AUTOSAR XML (schema 00050)
package /Safety_Gaurd/ComponentTypes
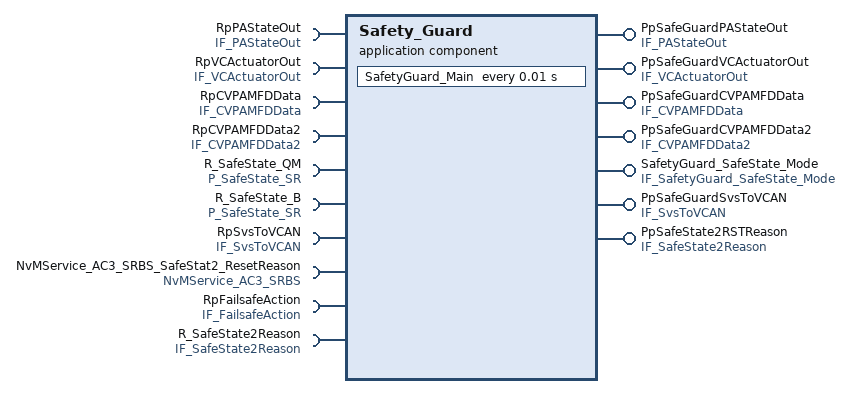
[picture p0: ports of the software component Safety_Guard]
  application sw component type Safety_Guard
    require port RpPAStateOut: nonqueued-receiver-com-spec=data-element=TbAP_PAStateOut_t, required-interface=IF_PAStateOut
    provide port PpSafeGuardPAStateOut: nonqueued-sender-com-spec{data-element=TbAP_PAStateOut_t, init-value=fields=[IeAP_e_PAMChimeRepnRate:0, IeAP_e_PAMVolSig:0, IeAP_e_FrntParkLEDSts:0, IeAP_e_PAMLedCtrl:0, IeAP_e_PAMChimeTyp:0, IeAP_e_ParkSensePopUpReq:0, IeAP_b_PAMRearBrkReq:0, IeAP_b_PAMRearCtrlSts:0]}, provided-interface=IF_PAStateOut
    require port RpVCActuatorOut: nonqueued-receiver-com-spec=data-element=TbAP_VCActuatorOut_t, required-interface=IF_VCActuatorOut
    provide port PpSafeGuardVCActuatorOut: nonqueued-sender-com-spec{data-element=TbAP_VCActuatorOut_t, init-value=fields=[IeAP_nm_StrwTrqReq:0, IeAP_a_DecelMax:0, IeAP_a_DecelMin:0, IeAP_a_JerkDecelMax:0, IeAP_a_JerkDecelMin:0, IeAP_a_AcclMin:0, IeAP_a_AcclMax:0, IeAP_da_JerkAcclMax:0, IeAP_da_JerkAcclMin:0, IeAP_cm_TrgtDist:0, IeAP_kph_TrgtVehSpd:0, IeAP_e_TurnIndicReq:0, IeAP_b_StandstillReq:0]}, provided-interface=IF_VCActuatorOut
    require port RpCVPAMFDData: nonqueued-receiver-com-spec=data-element=IFOD_Outputs_CVPAMFDData_t, required-interface=IF_CVPAMFDData
    require port RpCVPAMFDData2: nonqueued-receiver-com-spec=data-element=LMD_Outputs_CVPAMFDData2_t, required-interface=IF_CVPAMFDData2
    provide port PpSafeGuardCVPAMFDData: nonqueued-sender-com-spec{data-element=IFOD_Outputs_CVPAMFDData_t, init-value=fields=[IeFOD_e_FODHealth:0, IeFOD_e_FODConfidence:0]}, provided-interface=IF_CVPAMFDData
    provide port PpSafeGuardCVPAMFDData2: nonqueued-sender-com-spec{data-element=LMD_Outputs_CVPAMFDData2_t, init-value=fields=[{short-label=LMD_Outputs_ADASFDLANES1_s, fields=[IeLMD_e_FrameIndexLanes1:0, IeLMD_e_CntrAdasFdLanes1:0, IeLMD_e_Line1Confidence:0, IeLMD_e_Line2Confidence:0, IeLMD_e_Line3Confidence:0, IeLMD_e_Line4Confidence:0, IeLMD_m_Line1Offset:0, IeLMD_m_Line2Offset:0, IeLMD_m_Line3Offset:0, IeLMD_m_Line4Offset:0, IeLMD_rad_Line1Heading:0, IeLMD_rad_Line2Heading:0, IeLMD_rad_Line3Heading:0, IeLMD_rad_Line4Heading:0, IeLMD_m_Line1StartRange:0, IeLMD_m_Line2StartRange:0, IeLMD_m_Line3StartRange:0, IeLMD_m_Line4StartRange:0, IeLMD_m_Line1EndRange:0, IeLMD_m_Line2EndRange:0, IeLMD_m_Line3EndRange:0, IeLMD_m_Line4EndRange:0, IeLMD_e_Line1Curvature:0, IeLMD_e_Line2Curvature:0, IeLMD_e_Line3Curvature:0, IeLMD_e_Line4Curvature:0, IeLMD_e_Line1CurvatureRate:0, IeLMD_e_Line2CurvatureRate:0, IeLMD_e_Line3CurvatureRate:0, IeLMD_e_Line4CurvatureRate:0, IeLMD_e_Line1Type:0, IeLMD_e_Line2Type:0, IeLMD_e_Line3Type:0, IeLMD_e_Line4Type:0, IeLMD_e_LaneDetectionHealth:0, IeLMD_e_CameraStatus:0, IeLMD_e_CrcAdasFdLanes1:0, IeLMD_e_MsgCntrAdasFdLanes1:0, IeLMD_e_MacAdasFdLanes1:0, IeLMD_e_ReservedForFunctionalSafety1:0, Dummy1_1_b:0, Dummy2_1_b:0, Dummy3_1_b:0]}, {short-label=LMD_Outputs_ADASFDLANES2_s, fields=[IeLMD_e_FrameIndexLanes2:0, IeLMD_e_CntrAdasFdLanes2:0, IeLMD_e_LineSeg1Conf:0, IeLMD_e_LineSeg2Conf:0, IeLMD_e_LineSeg3Conf:0, IeLMD_e_LineSeg4Conf:0, IeLMD_e_LineSeg5Conf:0, IeLMD_e_LineSeg6Conf:0, IeLMD_e_LineSeg7Conf:0, IeLMD_e_LineSeg8Conf:0, IeLMD_m_LineSeg1X1:0, IeLMD_m_LineSeg2X1:0, IeLMD_m_LineSeg3X1:0, IeLMD_m_LineSeg4X1:0, IeLMD_m_LineSeg5X1:0, IeLMD_m_LineSeg6X1:0, IeLMD_m_LineSeg7X1:0, IeLMD_m_LineSeg8X1:0, IeLMD_m_LineSeg1X2:0, IeLMD_m_LineSeg2X2:0, IeLMD_m_LineSeg3X2:0, IeLMD_m_LineSeg4X2:0, IeLMD_m_LineSeg5X2:0, IeLMD_m_LineSeg6X2:0, IeLMD_m_LineSeg7X2:0, IeLMD_m_LineSeg8X2:0, IeLMD_m_LineSeg1Y1:0, IeLMD_m_LineSeg2Y1:0, IeLMD_m_LineSeg3Y1:0, IeLMD_m_LineSeg4Y1:0, IeLMD_m_LineSeg5Y1:0, IeLMD_m_LineSeg6Y1:0, IeLMD_m_LineSeg7Y1:0, IeLMD_m_LineSeg8Y1:0, IeLMD_m_LineSeg1Y2:0, IeLMD_m_LineSeg2Y2:0, IeLMD_m_LineSeg3Y2:0, IeLMD_m_LineSeg4Y2:0, IeLMD_m_LineSeg5Y2:0, IeLMD_m_LineSeg6Y2:0, IeLMD_m_LineSeg7Y2:0, IeLMD_m_LineSeg8Y2:0, IeLMD_e_CrcAdasFdLanes2:0, IeLMD_e_LineSeg1Id:0, IeLMD_e_LineSeg2Id:0, IeLMD_e_LineSeg3Id:0, IeLMD_e_LineSeg4Id:0, IeLMD_e_LineSeg5Id:0, IeLMD_e_LineSeg6Id:0, IeLMD_e_LineSeg7Id:0, IeLMD_e_LineSeg8Id:0, IeLMD_e_MsgCntrAdasFdLanes2:0, IeLMD_e_MacAdasFdLanes2:0, IeLMD_e_ReservedForFunctionalSafety2:0, Dummy1_2_b:0, Dummy2_2_b:0, Dummy3_2_b:0]}]}, provided-interface=IF_CVPAMFDData2
    require port R_SafeState_QM: nonqueued-receiver-com-spec{data-element=SafeStateOp, filter=data-filter-type=ALWAYS, init-value=constant-reference=init_SafeStateOp}, required-interface=P_SafeState_SR
    require port R_SafeState_B: nonqueued-receiver-com-spec{data-element=SafeStateOp, filter=data-filter-type=ALWAYS, init-value=constant-reference=init_SafeStateOp}, required-interface=P_SafeState_SR
    provide port SafetyGuard_SafeState_Mode: mode-switch-sender-com-spec{mode-group=Mode, queue-length=1}, provided-interface=IF_SafetyGuard_SafeState_Mode
    require port RpSvsToVCAN: nonqueued-receiver-com-spec{data-element=SvsToVCAN_t, filter=data-filter-type=ALWAYS, init-value=fields=[IeSVS_b_SPMScrnReq:0, IeSVS_b_ImgDefeatReqSts:0, IeSVS_b_MoreCamsReqSts:0, IeSVS_b_AUXCamReqSts:0, IeSVS_e_DispView2:0]}, required-interface=IF_SvsToVCAN
    provide port PpSafeGuardSvsToVCAN: nonqueued-sender-com-spec{data-element=SvsToVCAN_t, init-value=fields=[IeSVS_b_SPMScrnReq:0, IeSVS_b_ImgDefeatReqSts:0, IeSVS_b_MoreCamsReqSts:0, IeSVS_b_AUXCamReqSts:0, IeSVS_e_DispView2:0]}, provided-interface=IF_SvsToVCAN
    require port NvMService_AC3_SRBS_SafeStat2_ResetReason: required-com-specs=[WriteBlock, SetRamBlockStatus, ReadBlock, InvalidateNvBlock, GetErrorStatus, EraseBlock], required-interface=NvMService_AC3_SRBS
    require port RpFailsafeAction: nonqueued-receiver-com-spec{data-element=FailSafe_State, filter=data-filter-type=ALWAYS, init-value=0}, required-interface=IF_FailsafeAction
    require port R_SafeState2Reason: nonqueued-receiver-com-spec{data-element=FaultEnum_u16, filter=data-filter-type=ALWAYS, init-value=0}, required-interface=IF_SafeState2Reason
    provide port PpSafeState2RSTReason: nonqueued-sender-com-spec{data-element=FaultEnum_u16, init-value=0}, provided-interface=IF_SafeState2Reason
    behavior Safety_Guard_InternalBehavior: handle-termination-and-restart=NO-SUPPORT
      ar-typed-per-instance-memorys:
        data SafeStat2_ResetReason_MirrorBlock: sw-calibration-access=READ-ONLY, type=uint16
      timing event TMT_SafetyGuard_Main: start-on-event=SafetyGuard_Main, period=0.01
      per-instance-parameters:
        parameter data prototype SafeStat2_ResetReason_DefaultValue: sw-calibration-access=READ-WRITE, type=uint16, init-value=0
      runnable SafetyGuard_Main
        data-receive-point-by-arguments:
          9 x access:
            REC_RpCVPAMFDData_IFOD_Outputs_CVPAMFDData_t: accessed-variable=RpCVPAMFDData.IFOD_Outputs_CVPAMFDData_t
            REC_RpCVPAMFDData2_LMD_Outputs_CVPAMFDData2_t: accessed-variable=RpCVPAMFDData2.LMD_Outputs_CVPAMFDData2_t
            REC_RpPAStateOut_TbAP_PAStateOut_t: accessed-variable=RpPAStateOut.TbAP_PAStateOut_t
            REC_RpVCActuatorOut_TbAP_VCActuatorOut_t: accessed-variable=RpVCActuatorOut.TbAP_VCActuatorOut_t
            REC_R_SafeState_B_SafeStateOp: accessed-variable=R_SafeState_B.SafeStateOp
            REC_R_SafeState_QM_SafeStateOp: accessed-variable=R_SafeState_QM.SafeStateOp
            REC_RpSvsToVCAN_SvsToVCAN_t: accessed-variable=RpSvsToVCAN.SvsToVCAN_t
            REC_RpFailsafeAction_FailSafe_State: accessed-variable=RpFailsafeAction.FailSafe_State
            REC_R_SafeState2Reason_FaultEnum_u16: accessed-variable=R_SafeState2Reason.FaultEnum_u16
        data-send-points:
          6 x access:
            SEND_PpSafeGuardCVPAMFDData_IFOD_Outputs_CVPAMFDData_t: accessed-variable=PpSafeGuardCVPAMFDData.IFOD_Outputs_CVPAMFDData_t
            SEND_PpSafeGuardCVPAMFDData2_LMD_Outputs_CVPAMFDData2_t: accessed-variable=PpSafeGuardCVPAMFDData2.LMD_Outputs_CVPAMFDData2_t
            SEND_PpSafeGuardPAStateOut_TbAP_PAStateOut_t: accessed-variable=PpSafeGuardPAStateOut.TbAP_PAStateOut_t
            SEND_PpSafeGuardVCActuatorOut_TbAP_VCActuatorOut_t: accessed-variable=PpSafeGuardVCActuatorOut.TbAP_VCActuatorOut_t
            SEND_PpSafeGuardSvsToVCAN_SvsToVCAN_t: accessed-variable=PpSafeGuardSvsToVCAN.SvsToVCAN_t
            SEND_PpSafeState2RSTReason_FaultEnum_u16: accessed-variable=PpSafeState2RSTReason.FaultEnum_u16
        mode switch point SWITCH_SafetyGuard_SafeState_Mode_Mode: mode-group=SafetyGuard_SafeState_Mode.Mode
        sync call SC_NvMService_AC3_SRBS_SafeStat2_ResetReason_WriteBlock: operation=NvMService_AC3_SRBS_SafeStat2_ResetReason.WriteBlock
        sync call SC_NvMService_AC3_SRBS_SafeStat2_ResetReason_GetErrorStatus: operation=NvMService_AC3_SRBS_SafeStat2_ResetReason.GetErrorStatus
      swc service dependency SafeStat2_ResetReason: category=SERVICE, assigned-datas=role-based-data-assignment={role=defaultValue, used-parameter-element=SafeStat2_ResetReason_DefaultValue}, assigned-ports=role-based-port-assignment={port-prototype=NvMService_AC3_SRBS_SafeStat2_ResetReason, role=NvMService_AC3_SRBS}
        service-needs:
          nv block needs SafeStat2_ResetReason: n-data-sets=1, ram-block-status-control=API, reliability=NO-PROTECTION, restore-at-start=true, store-immediate=true
  swc implementation Safety_Guard_Implementation: programming-language=C, vendor-id=0, behavior=Safety_Guard_InternalBehavior
    code-descriptors:
      code Default: artifact-descriptors=autosar-engineering-object=category=SWSRC
